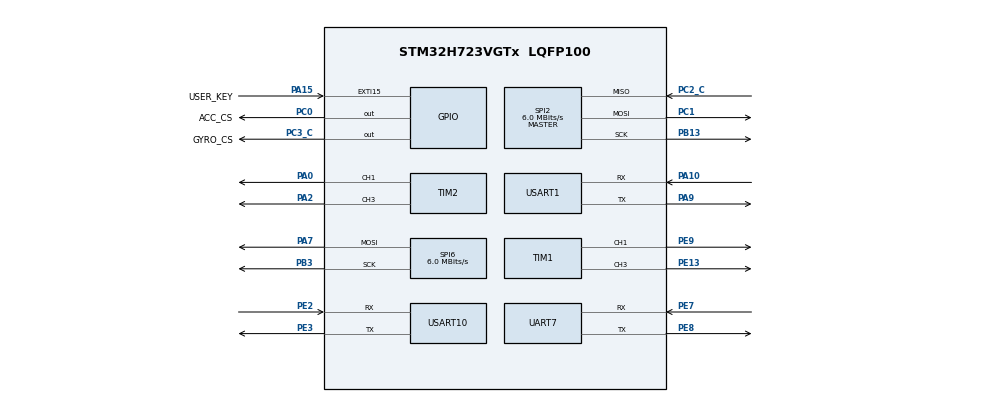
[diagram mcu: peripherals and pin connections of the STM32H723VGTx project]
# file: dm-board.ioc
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CORTEX_M7.default_mode_Activation=1
Dma.Request0=USART1_RX
Dma.Request1=USART1_TX
Dma.Request2=USART10_RX
Dma.Request3=UART7_RX
Dma.Request4=SPI2_RX
Dma.Request5=SPI2_TX
Dma.SPI2_RX.4.Direction=DMA_PERIPH_TO_MEMORY
Dma.SPI2_RX.4.EventEnable=DISABLE
Dma.SPI2_RX.4.FIFOMode=DMA_FIFOMODE_DISABLE
Dma.SPI2_RX.4.Instance=DMA1_Stream4
Dma.SPI2_RX.4.MemDataAlignment=DMA_MDATAALIGN_BYTE
Dma.SPI2_RX.4.MemInc=DMA_MINC_ENABLE
Dma.SPI2_RX.4.Mode=DMA_NORMAL
Dma.SPI2_RX.4.PeriphDataAlignment=DMA_PDATAALIGN_BYTE
Dma.SPI2_RX.4.PeriphInc=DMA_PINC_DISABLE
Dma.SPI2_RX.4.Polarity=HAL_DMAMUX_REQ_GEN_RISING
Dma.SPI2_RX.4.Priority=DMA_PRIORITY_LOW
Dma.SPI2_RX.4.RequestNumber=1
Dma.SPI2_RX.4.SignalID=NONE
Dma.SPI2_RX.4.SyncEnable=DISABLE
Dma.SPI2_RX.4.SyncPolarity=HAL_DMAMUX_SYNC_NO_EVENT
Dma.SPI2_RX.4.SyncRequestNumber=1
Dma.SPI2_RX.4.SyncSignalID=NONE
Dma.SPI2_TX.5.Direction=DMA_MEMORY_TO_PERIPH
Dma.SPI2_TX.5.EventEnable=DISABLE
Dma.SPI2_TX.5.FIFOMode=DMA_FIFOMODE_DISABLE
Dma.SPI2_TX.5.Instance=DMA1_Stream5
Dma.SPI2_TX.5.MemDataAlignment=DMA_MDATAALIGN_BYTE
Dma.SPI2_TX.5.MemInc=DMA_MINC_ENABLE
Dma.SPI2_TX.5.Mode=DMA_NORMAL
Dma.SPI2_TX.5.PeriphDataAlignment=DMA_PDATAALIGN_BYTE
Dma.SPI2_TX.5.PeriphInc=DMA_PINC_DISABLE
Dma.SPI2_TX.5.Polarity=HAL_DMAMUX_REQ_GEN_RISING
Dma.SPI2_TX.5.Priority=DMA_PRIORITY_LOW
Dma.SPI2_TX.5.RequestNumber=1
Dma.SPI2_TX.5.SignalID=NONE
Dma.SPI2_TX.5.SyncEnable=DISABLE
Dma.SPI2_TX.5.SyncPolarity=HAL_DMAMUX_SYNC_NO_EVENT
Dma.SPI2_TX.5.SyncRequestNumber=1
Dma.SPI2_TX.5.SyncSignalID=NONE
Dma.UART7_RX.3.Direction=DMA_PERIPH_TO_MEMORY
Dma.UART7_RX.3.EventEnable=DISABLE
Dma.UART7_RX.3.FIFOMode=DMA_FIFOMODE_DISABLE
Dma.UART7_RX.3.Instance=DMA1_Stream3
Dma.UART7_RX.3.MemDataAlignment=DMA_MDATAALIGN_BYTE
Dma.UART7_RX.3.MemInc=DMA_MINC_ENABLE
Dma.UART7_RX.3.Mode=DMA_NORMAL
Dma.UART7_RX.3.PeriphDataAlignment=DMA_PDATAALIGN_BYTE
Dma.UART7_RX.3.PeriphInc=DMA_PINC_DISABLE
Dma.UART7_RX.3.Polarity=HAL_DMAMUX_REQ_GEN_RISING
Dma.UART7_RX.3.Priority=DMA_PRIORITY_LOW
Dma.UART7_RX.3.RequestNumber=1
Dma.UART7_RX.3.SignalID=NONE
Dma.UART7_RX.3.SyncEnable=DISABLE
Dma.UART7_RX.3.SyncPolarity=HAL_DMAMUX_SYNC_NO_EVENT
Dma.UART7_RX.3.SyncRequestNumber=1
Dma.UART7_RX.3.SyncSignalID=NONE
Dma.USART10_RX.2.Direction=DMA_PERIPH_TO_MEMORY
Dma.USART10_RX.2.EventEnable=DISABLE
Dma.USART10_RX.2.FIFOMode=DMA_FIFOMODE_DISABLE
Dma.USART10_RX.2.Instance=DMA1_Stream2
Dma.USART10_RX.2.MemDataAlignment=DMA_MDATAALIGN_BYTE
Dma.USART10_RX.2.MemInc=DMA_MINC_ENABLE
Dma.USART10_RX.2.Mode=DMA_NORMAL
Dma.USART10_RX.2.PeriphDataAlignment=DMA_PDATAALIGN_BYTE
Dma.USART10_RX.2.PeriphInc=DMA_PINC_DISABLE
Dma.USART10_RX.2.Polarity=HAL_DMAMUX_REQ_GEN_RISING
Dma.USART10_RX.2.Priority=DMA_PRIORITY_LOW
Dma.USART10_RX.2.RequestNumber=1
Dma.USART10_RX.2.SignalID=NONE
Dma.USART10_RX.2.SyncEnable=DISABLE
Dma.USART10_RX.2.SyncPolarity=HAL_DMAMUX_SYNC_NO_EVENT
Dma.USART10_RX.2.SyncRequestNumber=1
Dma.USART10_RX.2.SyncSignalID=NONE
Dma.USART1_RX.0.Direction=DMA_PERIPH_TO_MEMORY
Dma.USART1_RX.0.EventEnable=DISABLE
Dma.USART1_RX.0.FIFOMode=DMA_FIFOMODE_DISABLE
Dma.USART1_RX.0.Instance=DMA1_Stream0
Dma.USART1_RX.0.MemDataAlignment=DMA_MDATAALIGN_BYTE
Dma.USART1_RX.0.MemInc=DMA_MINC_ENABLE
Dma.USART1_RX.0.Mode=DMA_NORMAL
Dma.USART1_RX.0.PeriphDataAlignment=DMA_PDATAALIGN_BYTE
Dma.USART1_RX.0.PeriphInc=DMA_PINC_DISABLE
Dma.USART1_RX.0.Polarity=HAL_DMAMUX_REQ_GEN_RISING
Dma.USART1_RX.0.Priority=DMA_PRIORITY_LOW
Dma.USART1_RX.0.RequestNumber=1
Dma.USART1_RX.0.SignalID=NONE
Dma.USART1_RX.0.SyncEnable=DISABLE
Dma.USART1_RX.0.SyncPolarity=HAL_DMAMUX_SYNC_NO_EVENT
Dma.USART1_RX.0.SyncRequestNumber=1
Dma.USART1_RX.0.SyncSignalID=NONE
Dma.USART1_TX.1.Direction=DMA_MEMORY_TO_PERIPH
Dma.USART1_TX.1.EventEnable=DISABLE
Dma.USART1_TX.1.FIFOMode=DMA_FIFOMODE_DISABLE
Dma.USART1_TX.1.Instance=DMA1_Stream1
Dma.USART1_TX.1.MemDataAlignment=DMA_MDATAALIGN_BYTE
Dma.USART1_TX.1.MemInc=DMA_MINC_ENABLE
Dma.USART1_TX.1.Mode=DMA_NORMAL
Dma.USART1_TX.1.PeriphDataAlignment=DMA_PDATAALIGN_BYTE
Dma.USART1_TX.1.PeriphInc=DMA_PINC_DISABLE
Dma.USART1_TX.1.Polarity=HAL_DMAMUX_REQ_GEN_RISING
Dma.USART1_TX.1.Priority=DMA_PRIORITY_LOW
Dma.USART1_TX.1.RequestNumber=1
Dma.USART1_TX.1.SignalID=NONE
Dma.USART1_TX.1.SyncEnable=DISABLE
Dma.USART1_TX.1.SyncPolarity=HAL_DMAMUX_SYNC_NO_EVENT
Dma.USART1_TX.1.SyncRequestNumber=1
Dma.USART1_TX.1.SyncSignalID=NONE
FREERTOS.INCLUDE_pcTaskGetTaskName=1
FREERTOS.INCLUDE_uxTaskGetStackHighWaterMark2=1
FREERTOS.INCLUDE_vTaskCleanUpResources=1
FREERTOS.INCLUDE_xEventGroupSetBitFromISR=1
FREERTOS.INCLUDE_xSemaphoreGetMutexHolder=1
FREERTOS.INCLUDE_xTaskAbortDelay=1
FREERTOS.INCLUDE_xTaskGetHandle=1
FREERTOS.Tasks01=defaultTask,24,128,StartDefaultTask,Default,NULL,Dynamic,NULL,NULL
FREERTOS.configENABLE_FPU=1
FREERTOS.configGENERATE_RUN_TIME_STATS=1
FREERTOS.configTOTAL_HEAP_SIZE=32864
FREERTOS.configUSE_NEWLIB_REENTRANT=1
FREERTOS.configUSE_STATS_FORMATTING_FUNCTIONS=1
Mcu.Family=STM32H7
Mcu.Name=STM32H723VGTx
Mcu.Package=LQFP100
NVIC.DMA1_Stream0_IRQn=true\:5\:0\:false\:false\:true\:true\:false\:true\:true
NVIC.DMA1_Stream1_IRQn=true\:5\:0\:false\:false\:true\:true\:false\:true\:true
NVIC.DMA1_Stream2_IRQn=true\:5\:0\:false\:false\:true\:true\:false\:true\:true
NVIC.DMA1_Stream3_IRQn=true\:5\:0\:false\:false\:true\:true\:false\:true\:true
NVIC.DMA1_Stream4_IRQn=true\:5\:0\:false\:false\:true\:true\:false\:true\:true
NVIC.DMA1_Stream5_IRQn=true\:5\:0\:false\:false\:true\:true\:false\:true\:true
NVIC.EXTI15_10_IRQn=true\:5\:0\:false\:false\:true\:true\:true\:true\:true
NVIC.PriorityGroup=NVIC_PRIORITYGROUP_4
NVIC.SPI2_IRQn=true\:5\:0\:false\:false\:true\:true\:true\:true\:true
NVIC.TIM23_IRQn=true\:15\:0\:false\:false\:true\:false\:false\:true\:true
NVIC.TIM6_DAC_IRQn=true\:5\:0\:false\:false\:true\:true\:true\:true\:true
NVIC.TimeBase=TIM23_IRQn
NVIC.TimeBaseIP=TIM23
NVIC.UART7_IRQn=true\:5\:0\:false\:false\:true\:true\:true\:true\:true
NVIC.USART10_IRQn=true\:5\:0\:false\:false\:true\:true\:true\:true\:true
NVIC.USART1_IRQn=true\:5\:0\:false\:false\:true\:true\:true\:true\:true
PA0.Signal=S_TIM2_CH1_ETR
PA10.Mode=Asynchronous
PA10.Signal=USART1_RX
PA15(JTDI).GPIO_Label=USER_KEY
PA15(JTDI).GPIO_ModeDefaultEXTI=GPIO_MODE_IT_FALLING
PA15(JTDI).Signal=GPXTI15
PA2.Signal=S_TIM2_CH3
PA7.Mode=TX_Only_Simplex_Unidirect_Master
PA7.Signal=SPI6_MOSI
PA9.Mode=Asynchronous
PA9.Signal=USART1_TX
PB13.Mode=Full_Duplex_Master
PB13.Signal=SPI2_SCK
PB3(JTDO/TRACESWO).Mode=TX_Only_Simplex_Unidirect_Master
PB3(JTDO/TRACESWO).Signal=SPI6_SCK
PC0.GPIO_Label=ACC_CS
PC0.Signal=GPIO_Output
PC1.Mode=Full_Duplex_Master
PC1.Signal=SPI2_MOSI
PC2_C.Mode=Full_Duplex_Master
PC2_C.Signal=SPI2_MISO
PC3_C.GPIO_Label=GYRO_CS
PC3_C.Signal=GPIO_Output
PE13.Signal=S_TIM1_CH3
PE2.Mode=Asynchronous
PE2.Signal=USART10_RX
PE3.Mode=Asynchronous
PE3.Signal=USART10_TX
PE7.Mode=Asynchronous
PE7.Signal=UART7_RX
PE8.Mode=Asynchronous
PE8.Signal=UART7_TX
PE9.Signal=S_TIM1_CH1
PH0-OSC_IN.Mode=HSE-External-Oscillator
PH0-OSC_IN.Signal=RCC_OSC_IN
PH1-OSC_OUT.Mode=HSE-External-Oscillator
PH1-OSC_OUT.Signal=RCC_OSC_OUT
ProjectManager.HeapSize=0x200
ProjectManager.StackSize=0x400
ProjectManager.TargetToolchain=CMake
RCC.ADCFreq_Value=96000000
RCC.APB1Freq_Value=120000000
RCC.APB2Freq_Value=120000000
RCC.APB3Freq_Value=120000000
RCC.APB4Freq_Value=120000000
RCC.CortexFreq_Value=480000000
RCC.D1PPRE=RCC_APB3_DIV2
RCC.D2PPRE1=RCC_APB1_DIV2
RCC.D2PPRE2=RCC_APB2_DIV2
RCC.D3PPRE=RCC_APB4_DIV2
RCC.DIVM1=2
RCC.DIVM2=2
RCC.DIVN1=40
RCC.DIVN2=16
RCC.DIVP1=1
RCC.DIVQ1=5
RCC.HCLKFreq_Value=240000000
RCC.HPRE=RCC_HCLK_DIV2
RCC.HSE_VALUE=24000000
RCC.PLLSourceVirtual=RCC_PLLSOURCE_HSE
RCC.SPI6CLockSelection=RCC_SPI6CLKSOURCE_HSE
RCC.SYSCLKFreq_VALUE=480000000
RCC.SYSCLKSource=RCC_SYSCLKSOURCE_PLLCLK
RCC.USBFreq_Value=96000000
SH.S_TIM1_CH1.0=TIM1_CH1,PWM Generation1 CH1
SH.S_TIM1_CH3.0=TIM1_CH3,Output Compare3 CH3
SH.S_TIM2_CH1_ETR.0=TIM2_CH1,Output Compare1 CH1
SH.S_TIM2_CH3.0=TIM2_CH3,Output Compare3 CH3
SPI2.BaudRatePrescaler=SPI_BAUDRATEPRESCALER_16
SPI2.CLKPhase=SPI_PHASE_2EDGE
SPI2.CLKPolarity=SPI_POLARITY_HIGH
SPI2.CalculateBaudRate=6.0 MBits/s
SPI2.DataSize=SPI_DATASIZE_8BIT
SPI2.Direction=SPI_DIRECTION_2LINES
SPI2.Mode=SPI_MODE_MASTER
SPI2.VirtualType=VM_MASTER
SPI6.BaudRatePrescaler=SPI_BAUDRATEPRESCALER_4
SPI6.CLKPhase=SPI_PHASE_2EDGE
SPI6.CalculateBaudRate=6.0 MBits/s
SPI6.DataSize=SPI_DATASIZE_8BIT
SPI6.Direction=SPI_DIRECTION_2LINES_TXONLY
SPI6.Mode=SPI_MODE_MASTER
SPI6.VirtualType=VM_MASTER
TIM1.Channel-Output\ Compare3\ CH3=TIM_CHANNEL_3
TIM1.Channel-PWM\ Generation1\ CH1=TIM_CHANNEL_1
TIM2.Channel-Output\ Compare1\ CH1=TIM_CHANNEL_1
TIM2.Channel-Output\ Compare3\ CH3=TIM_CHANNEL_3
USART1.VirtualMode-Asynchronous=VM_ASYNC
USART10.VirtualMode=VM_ASYNC
VP_FREERTOS_VS_CMSIS_V2.Mode=CMSIS_V2
VP_MEMORYMAP_VS_MEMORYMAP.Mode=CurAppReg
VP_RNG_VS_RNG.Mode=RNG_Activate
VP_SYS_VS_tim23.Mode=TIM23
VP_TIM6_VS_ClockSourceINT.Mode=Enable_Timer
board=custom

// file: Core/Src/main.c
/* USER CODE BEGIN Header */
/**
  ******************************************************************************
  * @file           : main.c
  * @brief          : Main program body
  ******************************************************************************
  * @attention
  *
  * Copyright (c) 2025 STMicroelectronics.
  * All rights reserved.
  *
  * This software is licensed under terms that can be found in the LICENSE file
  * in the root directory of this software component.
  * If no LICENSE file comes with this software, it is provided AS-IS.
  *
  ******************************************************************************
  */
/* USER CODE END Header */
#include "main.h"
#include "cmsis_os.h"
#include "dma.h"
#include "rng.h"
#include "spi.h"
#include "tim.h"
#include "usart.h"
#include "gpio.h"

/* USER CODE BEGIN Includes */
#include <bsp/uart.h>
#include <bsp/key.h>
#include <bsp/imu.h>
/* USER CODE END Includes */

void SystemClock_Config(void);
static void MPU_Config(void);
void MX_FREERTOS_Init(void);

/* USER CODE BEGIN 0 */
void HAL_GPIO_EXTI_Callback(uint16_t GPIO_Pin) {
  _bsp_key_exti_callback(GPIO_Pin);
}
/* USER CODE END 0 */

int main(void)
{

  /* MPU Configuration--------------------------------------------------------*/
  MPU_Config();

  /* MCU Configuration--------------------------------------------------------*/

  /* Reset of all peripherals, Initializes the Flash interface and the Systick. */
  HAL_Init();

  /* Configure the system clock */
  SystemClock_Config();

  /* Initialize all configured peripherals */
  MX_GPIO_Init();
  MX_DMA_Init();
  MX_USART1_UART_Init();
  MX_USART10_UART_Init();
  MX_UART7_Init();
  MX_SPI6_Init();
  MX_RNG_Init();
  MX_TIM1_Init();
  MX_TIM2_Init();
  MX_TIM6_Init();
  MX_SPI2_Init();
  /* USER CODE BEGIN 2 */
  bsp_uart_bind();
  bsp_key_init();
  bsp_imu_init();
  /* USER CODE END 2 */

  /* Init scheduler */
  osKernelInitialize();  /* Call init function for freertos objects (in cmsis_os2.c) */
  MX_FREERTOS_Init();

  /* Start scheduler */
  osKernelStart();

  /* We should never get here as control is now taken by the scheduler */

  /* Infinite loop */
  while (1)
  {

  }
}

void SystemClock_Config(void)
{
  RCC_OscInitTypeDef RCC_OscInitStruct = {0};
  RCC_ClkInitTypeDef RCC_ClkInitStruct = {0};

  /** Supply configuration update enable
  */
  HAL_PWREx_ConfigSupply(PWR_LDO_SUPPLY);

  /** Configure the main internal regulator output voltage
  */
  __HAL_PWR_VOLTAGESCALING_CONFIG(PWR_REGULATOR_VOLTAGE_SCALE0);

  while(!__HAL_PWR_GET_FLAG(PWR_FLAG_VOSRDY)) {}

  /** Initializes the RCC Oscillators according to the specified parameters
  * in the RCC_OscInitTypeDef structure.
  */
  RCC_OscInitStruct.OscillatorType = RCC_OSCILLATORTYPE_HSI48|RCC_OSCILLATORTYPE_HSE;
  RCC_OscInitStruct.HSEState = RCC_HSE_ON;
  RCC_OscInitStruct.HSI48State = RCC_HSI48_ON;
  RCC_OscInitStruct.PLL.PLLState = RCC_PLL_ON;
  RCC_OscInitStruct.PLL.PLLSource = RCC_PLLSOURCE_HSE;
  RCC_OscInitStruct.PLL.PLLM = 2;
  RCC_OscInitStruct.PLL.PLLN = 40;
  RCC_OscInitStruct.PLL.PLLP = 1;
  RCC_OscInitStruct.PLL.PLLQ = 5;
  RCC_OscInitStruct.PLL.PLLR = 2;
  RCC_OscInitStruct.PLL.PLLRGE = RCC_PLL1VCIRANGE_3;
  RCC_OscInitStruct.PLL.PLLVCOSEL = RCC_PLL1VCOWIDE;
  RCC_OscInitStruct.PLL.PLLFRACN = 0;
  if (HAL_RCC_OscConfig(&RCC_OscInitStruct) != HAL_OK)
  {
    Error_Handler();
  }

  /** Initializes the CPU, AHB and APB buses clocks
  */
  RCC_ClkInitStruct.ClockType = RCC_CLOCKTYPE_HCLK|RCC_CLOCKTYPE_SYSCLK
                              |RCC_CLOCKTYPE_PCLK1|RCC_CLOCKTYPE_PCLK2
                              |RCC_CLOCKTYPE_D3PCLK1|RCC_CLOCKTYPE_D1PCLK1;
  RCC_ClkInitStruct.SYSCLKSource = RCC_SYSCLKSOURCE_PLLCLK;
  RCC_ClkInitStruct.SYSCLKDivider = RCC_SYSCLK_DIV1;
  RCC_ClkInitStruct.AHBCLKDivider = RCC_HCLK_DIV2;
  RCC_ClkInitStruct.APB3CLKDivider = RCC_APB3_DIV2;
  RCC_ClkInitStruct.APB1CLKDivider = RCC_APB1_DIV2;
  RCC_ClkInitStruct.APB2CLKDivider = RCC_APB2_DIV2;
  RCC_ClkInitStruct.APB4CLKDivider = RCC_APB4_DIV2;

  if (HAL_RCC_ClockConfig(&RCC_ClkInitStruct, FLASH_LATENCY_3) != HAL_OK)
  {
    Error_Handler();
  }
}

 /* MPU Configuration */

void MPU_Config(void)
{
  MPU_Region_InitTypeDef MPU_InitStruct = {0};

  /* Disables the MPU */
  HAL_MPU_Disable();

  /** Initializes and configures the Region and the memory to be protected
  */
  MPU_InitStruct.Enable = MPU_REGION_ENABLE;
  MPU_InitStruct.Number = MPU_REGION_NUMBER0;
  MPU_InitStruct.BaseAddress = 0x0;
  MPU_InitStruct.Size = MPU_REGION_SIZE_4GB;
  MPU_InitStruct.SubRegionDisable = 0x87;
  MPU_InitStruct.TypeExtField = MPU_TEX_LEVEL0;
  MPU_InitStruct.AccessPermission = MPU_REGION_NO_ACCESS;
  MPU_InitStruct.DisableExec = MPU_INSTRUCTION_ACCESS_DISABLE;
  MPU_InitStruct.IsShareable = MPU_ACCESS_SHAREABLE;
  MPU_InitStruct.IsCacheable = MPU_ACCESS_NOT_CACHEABLE;
  MPU_InitStruct.IsBufferable = MPU_ACCESS_NOT_BUFFERABLE;

  HAL_MPU_ConfigRegion(&MPU_InitStruct);
  /* Enables the MPU */
  HAL_MPU_Enable(MPU_PRIVILEGED_DEFAULT);

}

void HAL_TIM_PeriodElapsedCallback(TIM_HandleTypeDef *htim)
{
  if (htim->Instance == TIM23)
  {
    HAL_IncTick();
  }
  /* USER CODE BEGIN Callback 1 */
  _bsp_key_tim_callback(htim);
  /* USER CODE END Callback 1 */
}

void Error_Handler(void)
{
  __disable_irq();
  while (1)
  {
  }
}
